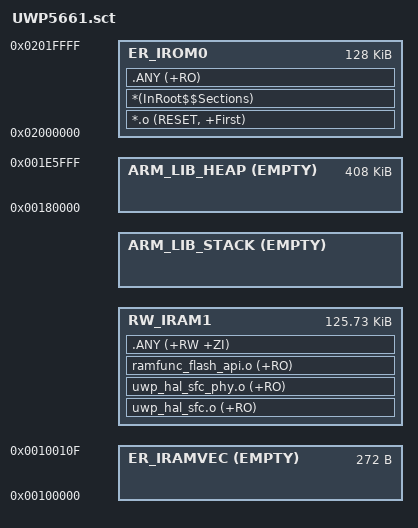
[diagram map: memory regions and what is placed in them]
#! armcc -E

#define UWP_IRAM_BASE         (0x00100000) /* RAM   size ??        */
#define UWP_DRAM_BASE         (0x00180000)
#define UWP_BOOT_FLASH_BASE   (0x02000000) /* 128k  for bootloader */
#define UWP_APP_FLASH_BASE    (0x02040000) /* 512k  for app        */
#define UWP_MODEM_FLASH_BASE  (0x020c0000) /* 640k  for modem      */
#define UWP_USER_FLASH_BASE   (0x02200000) /* 1280k for user data  */

#define UWP_IRAM_SIZE         (0x00080000) /* ???512k              */
#define UWP_DRAM_SIZE         (0x00066000) /* ???920k-512k=408k    */
#define UWP_BOOT_FLASH_SIZE   (0x00020000) /* 128k                 */
#define UWP_APP_FLASH_SIZE    (0x00080000) /* 512k                 */
#define UWP_MODEM_FLASH_SIZE  (0x000A0000) /* 640k                 */
#define UWP_USER_FLASH_SIZE   (0x00140000) /* 1280k                */

LR_IROM1 UWP_BOOT_FLASH_BASE UWP_BOOT_FLASH_SIZE  {                ; load region size_region
  ER_IROM0 UWP_BOOT_FLASH_BASE UWP_BOOT_FLASH_SIZE  {              ; load address = execution address
   *.o (RESET, +First)
   *(InRoot$$Sections)
   .ANY (+RO)
  }
  ; 8_byte_aligned(31 vect * 4 bytes) =  8_byte_aligned(0x10C) = 0x110
  ER_IRAMVEC UWP_IRAM_BASE EMPTY 0x110  {        ; Reserved for vectors
  }
  ; IRAM Size: Total(128KB) - Vector(272B) - Stack(2KB)
  RW_IRAM1 AlignExpr(+0, 8) (0x20000 - 0x110 - 0x800)  {
   uwp_hal_sfc.o (+RO)
   uwp_hal_sfc_phy.o (+RO)
   ramfunc_flash_api.o (+RO)
   .ANY (+RW +ZI)
  }
  ARM_LIB_STACK AlignExpr(+0, 8) EMPTY (UWP_IRAM_BASE + UWP_IRAM_SIZE - AlignExpr(ImageLimit(RW_IRAM1), 8))  {
  }
  ARM_LIB_HEAP  UWP_DRAM_BASE EMPTY UWP_DRAM_SIZE  {
  }
}
